VERSION ""

NS_ :

BS_:

BU_: Current_Sensor BMS
VAL_TABLE_ Cur_Measure_Error_Value_Table 1 "Current measure Error" 0 "Current measure OK" ;
VAL_TABLE_ Cur_Unit_Flag_Value_Table 1 "uA" 0 "mA" ;

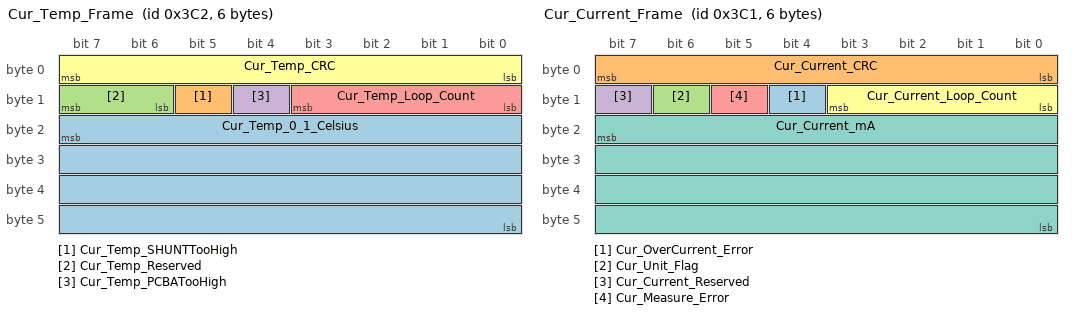
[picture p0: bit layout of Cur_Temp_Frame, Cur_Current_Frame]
BO_ 962 Cur_Temp_Frame: 6 Current_Sensor
 SG_ Cur_Temp_0_1_Celsius : 23|32@0- (0.1,0) [-214748364.8|214748364.7] "0.1¡æ"  BMS
 SG_ Cur_Temp_SHUNTTooHigh : 13|1@0+ (1,0) [0|1] ""  BMS
 SG_ Cur_Temp_Reserved : 15|2@0+ (1,0) [0|3] ""  BMS
 SG_ Cur_Temp_PCBATooHigh : 12|1@0+ (1,0) [0|1] ""  BMS
 SG_ Cur_Temp_Loop_Count : 11|4@0+ (1,0) [0|15] ""  BMS
 SG_ Cur_Temp_CRC : 7|8@0+ (1,0) [0|255] ""  BMS

BO_ 961 Cur_Current_Frame: 6 Current_Sensor
 SG_ Cur_OverCurrent_Error : 12|1@0+ (1,0) [0|1] ""  BMS
 SG_ Cur_Current_CRC : 7|8@0+ (1,0) [0|255] ""  BMS
 SG_ Cur_Unit_Flag : 14|1@0+ (1,0) [0|1] ""  BMS
 SG_ Cur_Current_Reserved : 15|1@0+ (1,0) [0|15] ""  BMS
 SG_ Cur_Measure_Error : 13|1@0+ (1,0) [0|1] ""  BMS
 SG_ Cur_Current_Loop_Count : 11|4@0+ (1,0) [0|15] ""  BMS
 SG_ Cur_Current_mA : 23|32@0- (1,0) [-2147483648|2147483647] "mA"  BMS

BA_DEF_ SG_  "GenSigSendType" ENUM  "Cyclic","OnWrite","OnWriteWithRepetition","OnChange","OnChangeWithRepetition","IfActive","IfActiveWithRepetition","NoSigSendType";
BA_DEF_ BO_  "GenMsgSendType" ENUM  "Cyclic","not_used","not_used","not_used","not_used","Cyclic","not_used","IfActive","NoMsgSendType";
BA_DEF_  "DBName" STRING ;
BA_DEF_  "BusType" STRING ;
BA_DEF_DEF_  "GenSigSendType" "Cyclic";
BA_DEF_DEF_  "GenMsgSendType" "NoMsgSendType";
BA_DEF_DEF_  "DBName" "";
BA_DEF_DEF_  "BusType" "CAN";
BA_ "DBName" "kaiburuisi_current_sensor";
VAL_ 961 Cur_Unit_Flag 1 "uA" 0 "mA" ;
VAL_ 961 Cur_Measure_Error 1 "Current measure Error" 0 "Current measure OK" ;
